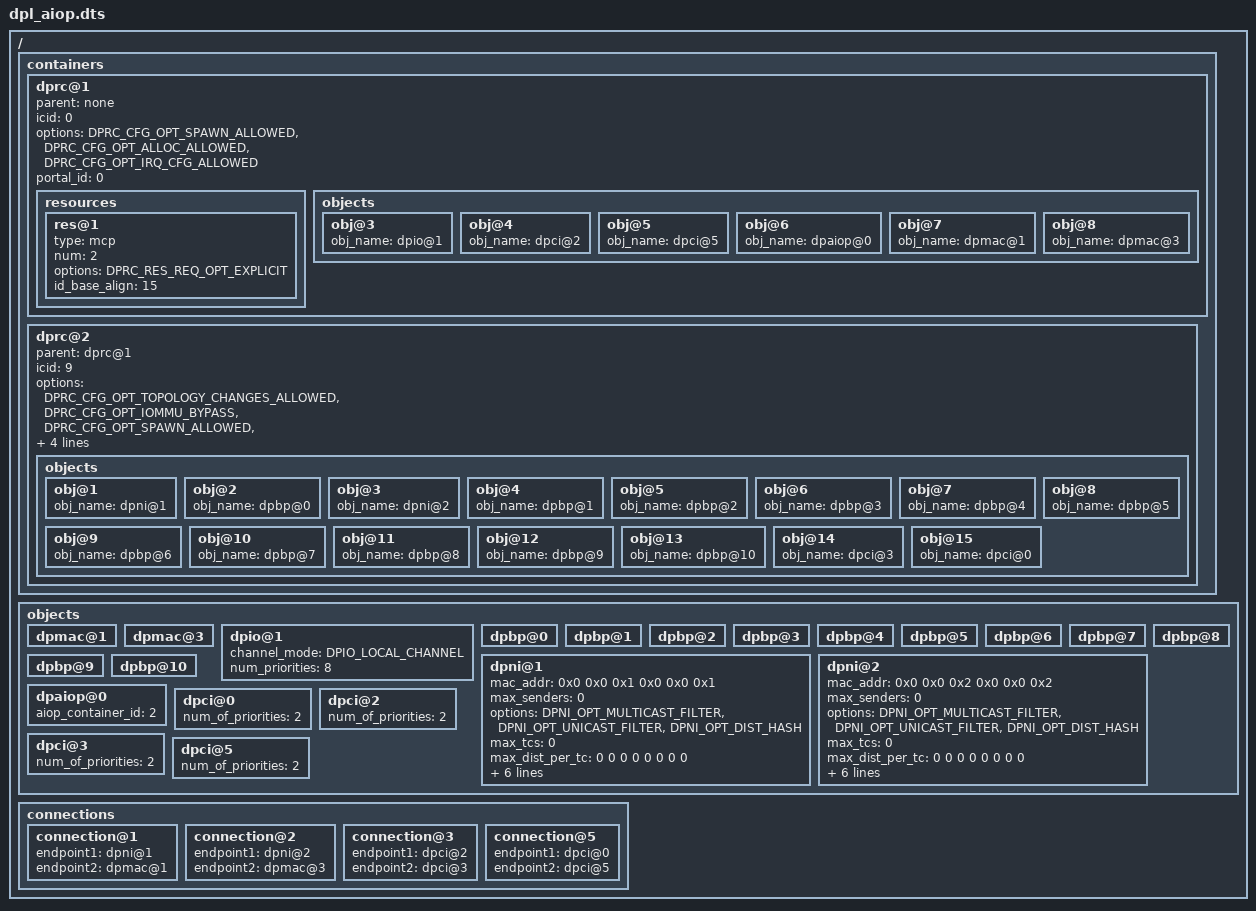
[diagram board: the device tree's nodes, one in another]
/dts-v1/;
/ {
	containers {
		dprc@1 {
			parent = "none";
			icid = <0>;
			options = "DPRC_CFG_OPT_SPAWN_ALLOWED" , "DPRC_CFG_OPT_ALLOC_ALLOWED", "DPRC_CFG_OPT_IRQ_CFG_ALLOWED";
			portal_id = <0>;
			resources {
				res@1 {
					type = "mcp";
					num = <2>;
					options = "DPRC_RES_REQ_OPT_EXPLICIT";
					id_base_align = <15>;
				};
			};
			objects {
				obj@3{
					obj_name = "dpio@1";
				};
				obj@4{
					obj_name = "dpci@2";
				};
				obj@5{
					obj_name = "dpci@5";
				};
				obj@6{
					obj_name = "dpaiop@0";
				};
				obj@7{
					obj_name = "dpmac@1";
				};
				obj@8{
					obj_name = "dpmac@3";
				};
			};
		};
		dprc@2 {
			parent = "dprc@1";
			icid = <9>;
			options = "DPRC_CFG_OPT_TOPOLOGY_CHANGES_ALLOWED" , "DPRC_CFG_OPT_IOMMU_BYPASS" , "DPRC_CFG_OPT_SPAWN_ALLOWED" , "DPRC_CFG_OPT_ALLOC_ALLOWED" , "DPRC_CFG_OPT_AIOP" , "DPRC_CFG_OPT_OBJ_CREATE_ALLOWED";
			portal_id = <3>;
			objects {
				obj@1{
					obj_name = "dpni@1";
				};
				obj@2{
					obj_name = "dpbp@0";
				};
				obj@3{
					obj_name = "dpni@2";
				};
				obj@4{
					obj_name = "dpbp@1";
				};
				obj@5{
					obj_name = "dpbp@2";
				};
				obj@6{
					obj_name = "dpbp@3";
				};
				obj@7{
					obj_name = "dpbp@4";
				};
				obj@8{
					obj_name = "dpbp@5";
				};
				obj@9{
					obj_name = "dpbp@6";
				};
				obj@10{
					obj_name = "dpbp@7";
				};
				obj@11{
					obj_name = "dpbp@8";
				};
				obj@12{
					obj_name = "dpbp@9";
				};
				obj@13{
					obj_name = "dpbp@10";
				};
				obj@14{
					obj_name = "dpci@3";
				};
				obj@15{
					obj_name = "dpci@0";
				};
			};
		};
	};
	objects {
		dpmac@1 {
		};
		dpmac@3 {
		};
		dpio@1 {
			channel_mode = "DPIO_LOCAL_CHANNEL";
			num_priorities = <8>;
		};
		dpbp@0 {
		};
		dpbp@1 {
		};
		dpbp@2 {
		};
		dpbp@3 {
		};
		dpbp@4 {
		};
		dpbp@5 {
		};
		dpbp@6 {
		};
		dpbp@7 {
		};
		dpbp@8 {
		};
		dpbp@9 {
		};
		dpbp@10 {
		};
		dpni@1{
			mac_addr = < 0x0 0x0 0x1 0x0 0x0 0x1 >; 
			max_senders = <0>;
			options = "DPNI_OPT_MULTICAST_FILTER" , "DPNI_OPT_UNICAST_FILTER" , "DPNI_OPT_DIST_HASH";
			max_tcs = <0>;
			max_dist_per_tc = < 0 0 0 0 0 0 0 0 >;
			max_unicast_filters = <0>;
			max_multicast_filters = <0>;
			max_vlan_filters = <0>;
			max_qos_entries = <0>;
			max_qos_key_size = <0>;
			max_dist_key_size = <0>;
		};
		dpni@2{
			mac_addr = < 0x0 0x0 0x2 0x0 0x0 0x2 >; /*eth_ipv4_udp*/
			max_senders = <0>;
			options = "DPNI_OPT_MULTICAST_FILTER" , "DPNI_OPT_UNICAST_FILTER" , "DPNI_OPT_DIST_HASH";
			max_tcs = <0>;
			max_dist_per_tc = < 0 0 0 0 0 0 0 0 >;
			max_unicast_filters = <0>;
			max_multicast_filters = <0>;
			max_vlan_filters = <0>;
			max_qos_entries = <0>;
			max_qos_key_size = <0>;
			max_dist_key_size = <0>;
		};
		dpaiop@0 {
			aiop_container_id = <2>;
		};
		dpci@0{
			num_of_priorities = <2>;
		};
		dpci@2{
			num_of_priorities = <2>;
		};
		dpci@3{
			num_of_priorities = <2>;
		};
		dpci@5{
			num_of_priorities = <2>;
		};
	};
	connections {
		connection@1 {
			endpoint1 = "dpni@1";
			endpoint2= "dpmac@1";
		};
		connection@2 {
			endpoint1 = "dpni@2";
			endpoint2= "dpmac@3";
		};
		connection@3 {
			endpoint1 = "dpci@2";
			endpoint2= "dpci@3";
		};
		connection@5 {
			endpoint1 = "dpci@0";
			endpoint2= "dpci@5";
		};
	};
};
